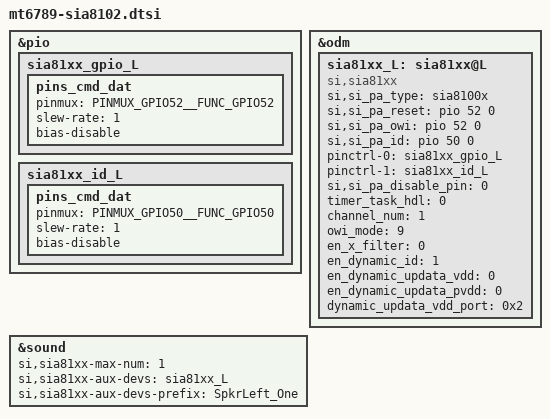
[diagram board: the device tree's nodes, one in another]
/* Copyright (c) 2018, The Linux Foundation. All rights reserved.
 *
 * This program is free software; you can redistribute it and/or modify
 * it under the terms of the GNU General Public License version 2 and
 * only version 2 as published by the Free Software Foundation.
 *
 * This program is distributed in the hope that it will be useful,
 * but WITHOUT ANY WARRANTY; without even the implied warranty of
 * MERCHANTABILITY or FITNESS FOR A PARTICULAR PURPOSE.  See the
 * GNU General Public License for more details.
 */

&pio {
	sia81xx_gpio_L: sia81xx_gpio_L {
		pins_cmd_dat {
			pinmux = <PINMUX_GPIO52__FUNC_GPIO52>;
			slew-rate = <1>;
			bias-disable;
		};
	};
	

        sia81xx_id_L: sia81xx_id_L {
                pins_cmd_dat {
                        pinmux = <PINMUX_GPIO50__FUNC_GPIO50>;
                        slew-rate = <1>;
                        bias-disable;
                };
        };
};

&odm {
	sia81xx_L: sia81xx@L {
		compatible = "si,sia81xx";
		si,si_pa_type = "sia8100x";
		si,si_pa_reset = <&pio 52 0>;
		si,si_pa_owi = <&pio 52 0>;
		si,si_pa_id = <&pio 50 0>;
		pinctrl-names = "si_pa_gpio","si_pa_id";
		pinctrl-0 = <&sia81xx_gpio_L>;
		pinctrl-1 = <&sia81xx_id_L>;
		si,si_pa_disable_pin = <0>;
		
		/* the same value share a same task
		 * valid value range : 0 ~ 7 */
		timer_task_hdl = <0>;
		channel_num = <1>;
		owi_mode = <9>;
		en_x_filter = <0>;
		en_dynamic_id = <1>;
		en_dynamic_updata_vdd = <0>;
		en_dynamic_updata_pvdd = <0>;
		dynamic_updata_vdd_port = <0x2>;
	};
};

&sound {
	si,sia81xx-max-num = <1>;
	si,sia81xx-aux-devs = <&sia81xx_L>;
	si,sia81xx-aux-devs-prefix = "SpkrLeft_One";
};
